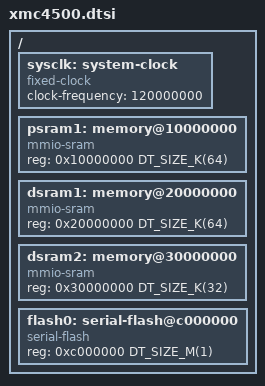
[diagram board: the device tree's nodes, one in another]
/*
 * Copyright (c) 2020 Linumiz
 * Author: Parthiban Nallathambi <parthiban@linumiz.com>
 *
 * SPDX-License-Identifier: Apache-2.0
 */

#include <mem.h>
#include <infineon/xmc4xxx.dtsi>

/ {

	sysclk: system-clock {
		compatible = "fixed-clock";
		clock-frequency = <120000000>;
		#clock-cells = <0>;
	};
	
	/* TODO: Add psram1 & dsram2 to MEMORY layout of linker */
	psram1: memory@10000000 {
		compatible = "mmio-sram";
	};

	dsram1: memory@20000000 {
		compatible = "mmio-sram";
	};

	dsram2: memory@30000000 {
		compatible = "mmio-sram";
	};

	flash0: serial-flash@c000000 {
		compatible = "serial-flash";
	};
};

&psram1 {
	reg = <0x10000000 DT_SIZE_K(64)>;
};

&dsram1 {
	reg = <0x20000000 DT_SIZE_K(64)>;
};

&dsram2 {
	reg = <0x30000000 DT_SIZE_K(32)>;
};

&flash0 {
	reg = <0xc000000 DT_SIZE_M(1)>;
};
